# EFR32MG24B310F1536IM48 register map
Vendor: Silicon Labs; Series: EFR32; File version: B
Registers are 32-bit, read-write, reset 0x0 unless marked. A register's access mark holds for its fields unless they carry their own. Offsets are from the block's base; [hi:lo] are bit positions; {n}, {i} and the like mark numbered series.

## SMU_NS — SMU_NS Registers
Base 0x54008000
Same registers: SMU_S 0x44008000
0x00 IPVERSION ro reset 0x3
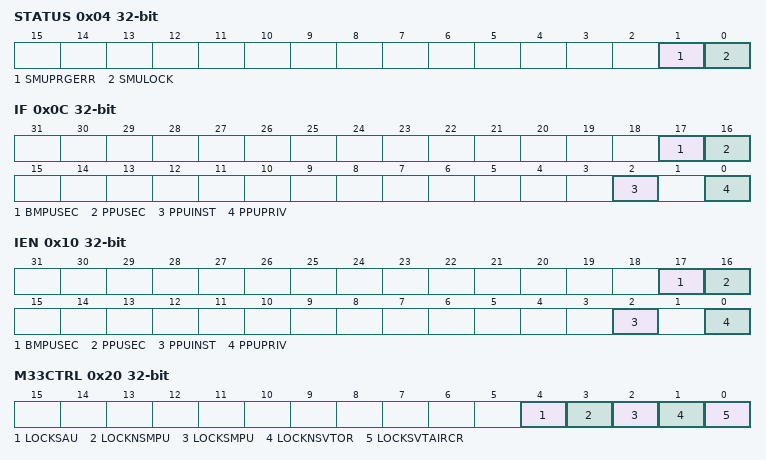
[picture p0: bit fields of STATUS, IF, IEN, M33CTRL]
0x04 STATUS ro
  [1] SMUPRGERR — SMU Programming Error
  [0] SMULOCK
    0=UNLOCKED; 1=LOCKED
0x08 LOCK wo
  [23:0] SMULOCKKEY
    0xACCE55=UNLOCK (Unlocks Registers)
0x0C IF
  [17] BMPUSEC — BMPU Security Interrupt Flag
  [16] PPUSEC — PPU Security Interrupt Flag
  [2] PPUINST — PPU Instruction Interrupt Flag
  [0] PPUPRIV — PPU Privilege Interrupt Flag
0x10 IEN
  [17] BMPUSEC — BMPU Security Interrupt Enable
  [16] PPUSEC — PPU Security Interrupt Enable
  [2] PPUINST — PPU Instruction Interrupt Enable
  [0] PPUPRIV — PPU Privilege Interrupt Enable
0x20 M33CTRL — Holds the M33 control settings
  [4] LOCKSAU — New BitField
  [3] LOCKNSMPU — New BitField
  [2] LOCKSMPU — New BitField
  [1] LOCKNSVTOR — New BitField
  [0] LOCKSVTAIRCR — New BitField
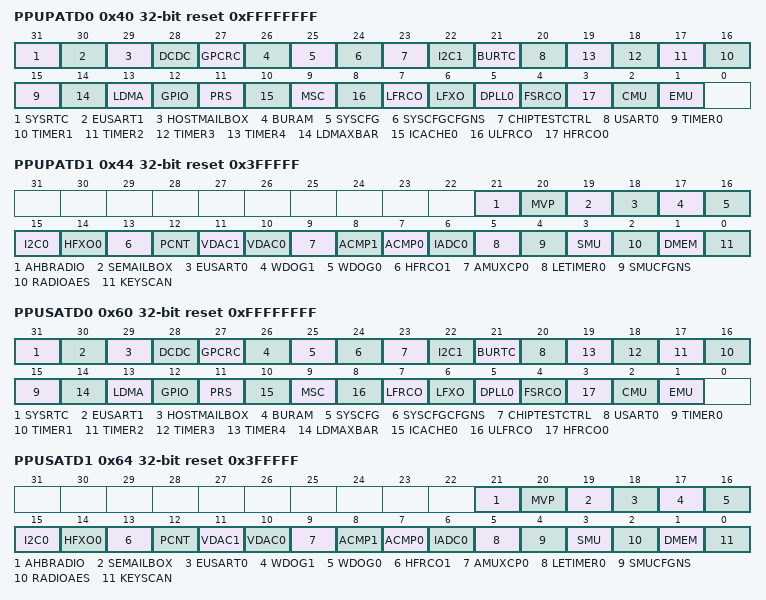
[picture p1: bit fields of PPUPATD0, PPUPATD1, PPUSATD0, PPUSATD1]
0x40 PPUPATD0 reset 0xFFFFFFFF — Set peripheral bits to 1 to mark as privileged access only
  [31] SYSRTC — SYSRTC Privileged Access
  [30] EUSART1 — EUSART1 Privileged Access
  [29] HOSTMAILBOX — HOSTMAILBOX Privileged Access
  [28] DCDC — DCDC Privileged Access
  [27] GPCRC — GPCRC Privileged Access
  [26] BURAM — BURAM Privileged Access
  [25] SYSCFG — SYSCFG Privileged Access
  [24] SYSCFGCFGNS — SYSCFGCFGNS Privileged Access
  [23] CHIPTESTCTRL — CHIPTESTCTRL Privileged Access
  [22] I2C1 — I2C1 Privileged Access
  [21] BURTC — BURTC Privileged Access
  [20] USART0 — USART0 Privileged Access
  [n+15] TIMER{n} (n=0..4) — TIMER{n} Privileged Access
  [14] LDMAXBAR — LDMAXBAR Privileged Access
  [13] LDMA — LDMA Privileged Access
  [12] GPIO — GPIO Privileged Access
  [11] PRS — PRS Privileged Access
  [10] ICACHE0 — ICACHE0 Privileged Access
  [9] MSC — MSC Privileged Access
  [8] ULFRCO — ULFRCO Privileged Access
  [7] LFRCO — LFRCO Privileged Access
  [6] LFXO — LFXO Privileged Access
  [5] DPLL0 — DPLL0 Privileged Access
  [4] FSRCO — FSRCO Privileged Access
  [3] HFRCO0 — HFRCO0 Privileged Access
  [2] CMU — CMU Privileged Access
  [1] EMU — EMU Privileged Access
0x44 PPUPATD1 reset 0x3FFFFF — Set peripheral bits to 1 to mark as privileged access only
  [21] AHBRADIO — AHBRADIO Privileged Access
  [20] MVP — MVP Privileged Access
  [19] SEMAILBOX — SEMAILBOX Privileged Access
  [18] EUSART0 — EUSART0 Privileged Access
  [17] WDOG1 — WDOG1 Privileged Access
  [16] WDOG0 — WDOG0 Privileged Access
  [15] I2C0 — I2C0 Privileged Access
  [14] HFXO0 — HFXO0 Privileged Access
  [13] HFRCO1 — HFRCO1 Privileged Access
  [12] PCNT — PCNT Privileged Access
  [11] VDAC1 — VDAC1 Privileged Access
  [10] VDAC0 — VDAC0 Privileged Access
  [9] AMUXCP0 — AMUXCP0 Privileged Access
  [8] ACMP1 — ACMP1 Privileged Access
  [7] ACMP0 — ACMP0 Privileged Access
  [6] IADC0 — IADC0 Privileged Access
  [5] LETIMER0 — LETIMER0 Privileged Access
  [4] SMUCFGNS — SMUCFGNS Privileged Access
  [3] SMU — SMU Privileged Access
  [2] RADIOAES — RADIOAES Privileged Access
  [1] DMEM — DMEM Privileged Access
  [0] KEYSCAN — KEYSCAN Privileged Access
0x60 PPUSATD0 reset 0xFFFFFFFF — Set peripheral bits to 1 to mark as secure access only
  [31] SYSRTC — SYSRTC Secure Access
  [30] EUSART1 — EUSART1 Secure Access
  [29] HOSTMAILBOX — HOSTMAILBOX Secure Access
  [28] DCDC — DCDC Secure Access
  [27] GPCRC — GPCRC Secure Access
  [26] BURAM — BURAM Secure Access
  [25] SYSCFG — SYSCFG Secure Access
  [24] SYSCFGCFGNS — SYSCFGCFGNS Secure Access
  [23] CHIPTESTCTRL — CHIPTESTCTRL Secure Access
  [22] I2C1 — I2C1 Secure Access
  [21] BURTC — BURTC Secure Access
  [20] USART0 — USART0 Secure Access
  [n+15] TIMER{n} (n=0..4) — TIMER{n} Secure Access
  [14] LDMAXBAR — LDMAXBAR Secure Access
  [13] LDMA — LDMA Secure Access
  [12] GPIO — GPIO Secure Access
  [11] PRS — PRS Secure Access
  [10] ICACHE0 — ICACHE0 Secure Access
  [9] MSC — MSC Secure Access
  [8] ULFRCO — ULFRCO Secure Access
  [7] LFRCO — LFRCO Secure Access
  [6] LFXO — LFXO Secure Access
  [5] DPLL0 — DPLL0 Secure Access
  [4] FSRCO — FSRCO Secure Access
  [3] HFRCO0 — HFRCO0 Secure Access
  [2] CMU — CMU Secure Access
  [1] EMU — EMU Secure Access
0x64 PPUSATD1 reset 0x3FFFFF — Set peripheral bits to 1 to mark as secure access only
  [21] AHBRADIO — AHBRADIO Secure Access
  [20] MVP — MVP Secure Access
  [19] SEMAILBOX — SEMAILBOX Secure Access
  [18] EUSART0 — EUSART0 Secure Access
  [17] WDOG1 — WDOG1 Secure Access
  [16] WDOG0 — WDOG0 Secure Access
  [15] I2C0 — I2C0 Secure Access
  [14] HFXO0 — HFXO0 Secure Access
  [13] HFRCO1 — HFRCO1 Secure Access
  [12] PCNT — PCNT Secure Access
  [11] VDAC1 — VDAC1 Secure Access
  [10] VDAC0 — VDAC0 Secure Access
  [9] AMUXCP0 — AMUXCP0 Secure Access
  [8] ACMP1 — ACMP1 Secure Access
  [7] ACMP0 — ACMP0 Secure Access
  [6] IADC0 — IADC0 Secure Access
  [5] LETIMER0 — LETIMER0 Secure Access
  [4] SMUCFGNS — SMUCFGNS Secure Access
  [3] SMU — SMU Secure Access
  [2] RADIOAES — RADIOAES Secure Access
  [1] DMEM — DMEM Secure Access
  [0] KEYSCAN — KEYSCAN Secure Access
0x140 PPUFS ro
  [7:0] PPUFSPERIPHID — Peripheral ID
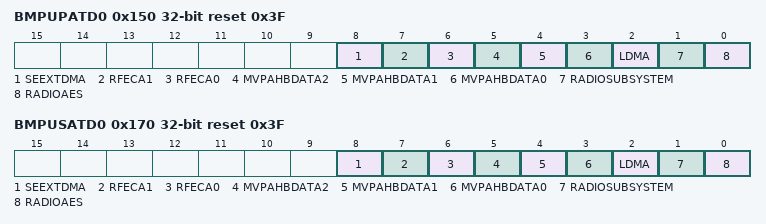
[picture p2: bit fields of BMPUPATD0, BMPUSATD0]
0x150 BMPUPATD0 reset 0x3F — Set master bits to 1 to mark as a privileged master
  [8] SEEXTDMA — SEEXTDMA privileged mode
  [7] RFECA1 — RFECA1 privileged mode
  [6] RFECA0 — RFECA0 privileged mode
  [5] MVPAHBDATA2 — MVPAHBDATA2 privileged mode
  [4] MVPAHBDATA1 — MVPAHBDATA1 privileged mode
  [3] MVPAHBDATA0 — MVPAHBDATA0 privileged mode
  [2] LDMA — MCU LDMA privileged mode
  [1] RADIOSUBSYSTEM — RADIO subsystem manager privileged mode
  [0] RADIOAES — RADIO AES DMA privileged mode
0x170 BMPUSATD0 reset 0x3F — Set master bits to 1 to mark as a secure master
  [8] SEEXTDMA — SEEXTDMA secure mode
  [7] RFECA1 — RFECA1 secure mode
  [6] RFECA0 — RFECA0 secure mode
  [5] MVPAHBDATA2 — MVPAHBDATA2 secure mode
  [4] MVPAHBDATA1 — MVPAHBDATA1 secure mode
  [3] MVPAHBDATA0 — MVPAHBDATA0 secure mode
  [2] LDMA — MCU LDMA secure mode
  [1] RADIOSUBSYSTEM — RADIO subsystem manager secure mode
  [0] RADIOAES — RADIOAES DMA secure mode
0x250 BMPUFS ro
  [7:0] BMPUFSMASTERID — Bus Manager ID
0x254 BMPUFSADDR ro
  [31:0] BMPUFSADDR — Fault Address
0x260 ESAURTYPES0
  [12] ESAUR3NS — Region 3 Non-Secure
0x264 ESAURTYPES1
  [12] ESAUR11NS — Region 11 Non-Secure
0x270 ESAUMRB01 reset 0xA000000
  [27:12] ESAUMRB01 — Moveable Region Boundary
0x274 ESAUMRB12 reset 0xC000000
  [27:12] ESAUMRB12 — Moveable Region Boundary
0x280 ESAUMRB45 reset 0x2000000
  [27:12] ESAUMRB45 — Moveable Region Boundary
0x284 ESAUMRB56 reset 0x4000000
  [27:12] ESAUMRB56 — Moveable Region Boundary
